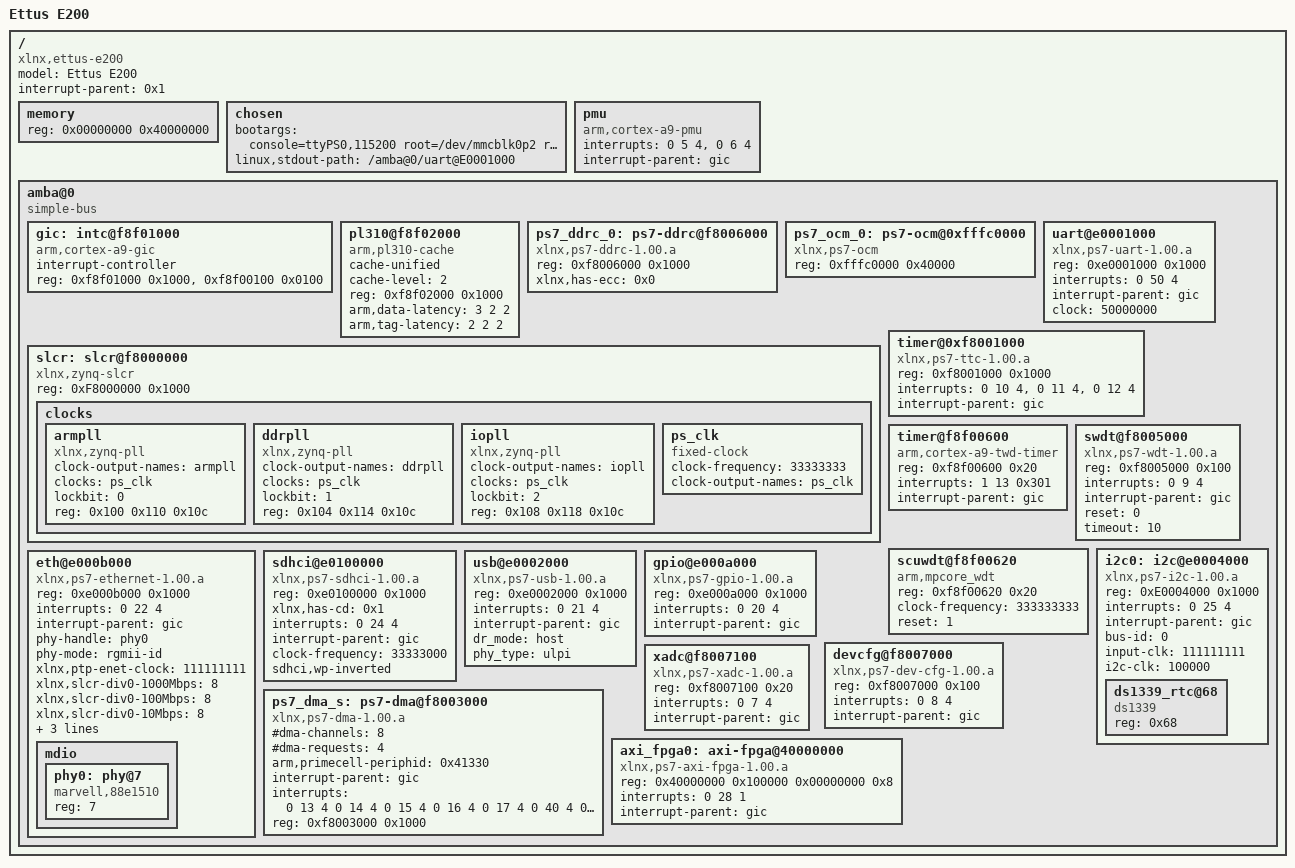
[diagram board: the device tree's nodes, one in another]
/dts-v1/;

/ {
	model = "Ettus E200";
	compatible = "xlnx,ettus-e200";
	#address-cells = <0x1>;
	#size-cells = <0x1>;
	interrupt-parent = <0x1>;

	memory {
		device_type = "memory";
		reg = <0x00000000 0x40000000>;
	};
	chosen {
		bootargs = "console=ttyPS0,115200 root=/dev/mmcblk0p2 rw rootwait earlyprintk";
		linux,stdout-path = "/amba@0/uart@E0001000";
	};

	pmu {
		compatible = "arm,cortex-a9-pmu";
		interrupts = <0 5 4>, <0 6 4>;
		interrupt-parent = <&gic>;
	};

	amba@0 {
		compatible = "simple-bus";
		#address-cells = <0x1>;
		#size-cells = <0x1>;
		ranges;

		gic: intc@f8f01000 {
			interrupt-controller;
			compatible = "arm,cortex-a9-gic";
			#interrupt-cells = <3>;
			reg = <0xf8f01000 0x1000>,
			      <0xf8f00100 0x0100>;
		};

		pl310@f8f02000 {
			compatible = "arm,pl310-cache";
			cache-unified;
			cache-level = <2>;
			reg = <0xf8f02000 0x1000>;
			arm,data-latency = <3 2 2>;
			arm,tag-latency = <2 2 2>;
		};

		ps7_ddrc_0: ps7-ddrc@f8006000 {
			compatible = "xlnx,ps7-ddrc-1.00.a", "xlnx,ps7-ddrc";
			reg = <0xf8006000 0x1000>;
			xlnx,has-ecc = <0x0>;
		} ;

		ps7_ocm_0: ps7-ocm@0xfffc0000 {
			compatible = "xlnx,ps7-ocm";
			reg = <0xfffc0000 0x40000>; /* 256k */
		};

		uart@e0001000 {
			compatible = "xlnx,ps7-uart-1.00.a";
			reg = <0xe0001000 0x1000>;
			interrupts = <0 50 4>;
			interrupt-parent = <&gic>;
			clock = <50000000>;
		};

		slcr: slcr@f8000000 {
			compatible = "xlnx,zynq-slcr";
			reg = <0xF8000000 0x1000>;
			clocks {
				#address-cells = <1>;
				#size-cells = <0>;
				armpll: armpll {
					#clock-cells = <0>;
					clock-output-names = "armpll";
					clocks = <&ps_clk>;
					compatible = "xlnx,zynq-pll";
					lockbit = <0>;
					reg = < 0x100 0x110 0x10c >;
				} ;
				ddrpll: ddrpll {
					#clock-cells = <0>;
					clock-output-names = "ddrpll";
					clocks = <&ps_clk>;
					compatible = "xlnx,zynq-pll";
					lockbit = <1>;
					reg = < 0x104 0x114 0x10c >;
				} ;
				iopll: iopll {
					#clock-cells = <0>;
					clock-output-names = "iopll";
					clocks = <&ps_clk>;
					compatible = "xlnx,zynq-pll";
					lockbit = <2>;
					reg = < 0x108 0x118 0x10c >;
				} ;
				ps_clk: ps_clk {
					#clock-cells = <0>;
					clock-frequency = <33333333>;
					clock-output-names = "ps_clk";
					compatible = "fixed-clock";
				} ;
			} ;
		};

		timer@0xf8001000 {
			compatible = "xlnx,ps7-ttc-1.00.a";
			reg = <0xf8001000 0x1000>;
			interrupts = <0 10 4>,<0 11 4>,<0 12 4>;
			interrupt-parent = <&gic>;
		};

		timer@f8f00600 {
			compatible = "arm,cortex-a9-twd-timer";
			reg = <0xf8f00600 0x20>;
			interrupts = <1 13 0x301>;
			interrupt-parent = <&gic>;
		};

		swdt@f8005000 {
			device_type = "watchdog";
			compatible = "xlnx,ps7-wdt-1.00.a";
			reg = <0xf8005000 0x100>;
			interrupts = <0 9 4>;
			interrupt-parent = <&gic>;
			reset = <0>;
			timeout = <10>;
		};

		scuwdt@f8f00620 {
			device_type = "watchdog";
			compatible = "arm,mpcore_wdt";
			reg = <0xf8f00620 0x20>;
			clock-frequency = <333333333>;
			reset = <1>;
		};

		eth@e000b000 {
			compatible = "xlnx,ps7-ethernet-1.00.a";
			reg = <0xe000b000 0x1000>;
			interrupts = <0 22 4>;
			interrupt-parent = <&gic>;
			phy-handle = <&phy0>;
			phy-mode = "rgmii-id";
			xlnx,ptp-enet-clock = <111111111>;
			xlnx,slcr-div0-1000Mbps = <8>;
			xlnx,slcr-div0-100Mbps = <8>;
			xlnx,slcr-div0-10Mbps = <8>;
			xlnx,slcr-div1-1000Mbps = <1>;
			xlnx,slcr-div1-100Mbps = <5>;
			xlnx,slcr-div1-10Mbps = <50>;
			#address-cells = <0x1>;
			#size-cells = <0x0>;
			mdio {
				#address-cells = <1>;
				#size-cells = <0>;
				phy0: phy@7 {
					compatible = "marvell,88e1510";
					device_type = "ethernet-phy";
					reg = <7>;
				};
			};
		};

		i2c0: i2c@e0004000 {
			compatible = "xlnx,ps7-i2c-1.00.a";
			reg = <0xE0004000 0x1000>;
			interrupts = <0 25 4>;
			interrupt-parent = <&gic>;
			bus-id = <0>;
			input-clk = <111111111>;
			i2c-clk = <100000>;

			#address-cells = <1>;
			#size-cells = <0>;

			ds1339_rtc@68 {
				compatible = "ds1339";
				reg = <0x68>;
			};
		};

		sdhci@e0100000 {
			compatible = "xlnx,ps7-sdhci-1.00.a";
			reg = <0xe0100000 0x1000>;
			xlnx,has-cd = <0x1>;
			interrupts = <0 24 4>;
			interrupt-parent = <&gic>;
			clock-frequency = <33333000>;
			sdhci,wp-inverted;
		};

		usb@e0002000 {
			compatible = "xlnx,ps7-usb-1.00.a";
			reg = <0xe0002000 0x1000>;
			interrupts = <0 21 4>;
			interrupt-parent = <&gic>;
			dr_mode = "host";
			phy_type = "ulpi";
		};

		gpio@e000a000 {
			compatible = "xlnx,ps7-gpio-1.00.a";
			reg = <0xe000a000 0x1000>;
			interrupts = <0 20 4>;
			interrupt-parent = <&gic>;
		};

		devcfg@f8007000 {
			compatible = "xlnx,ps7-dev-cfg-1.00.a";
			reg = <0xf8007000 0x100>;
			interrupts = <0 8 4>;
			interrupt-parent = <&gic>;
		};

		xadc@f8007100 {
			compatible = "xlnx,ps7-xadc-1.00.a";
			reg = <0xf8007100 0x20>;
			interrupts = <0 7 4>;
			interrupt-parent = <&gic>;
		};
		ps7_dma_s: ps7-dma@f8003000 {
			#dma-cells = <1>;
			#dma-channels = <8>;
			#dma-requests = <4>;
			arm,primecell-periphid = <0x41330>;
			compatible = "xlnx,ps7-dma-1.00.a", "arm,primecell", "arm,pl330";
			interrupt-parent = <&gic>;
			interrupts = < 0 13 4 0 14 4 0 15 4 0 16 4 0 17 4 0 40 4 0 41 4 0 42 4 0 43 4 >;
			reg = < 0xf8003000 0x1000 >;
		} ;
		axi_fpga0: axi-fpga@40000000 {
			compatible = "xlnx,ps7-axi-fpga-1.00.a";
			reg = <0x40000000 0x100000
				0x00000000 0x8>;
			interrupts = <0 28 1>;
			interrupt-parent = <&gic>;
                };
	};
};
